# Z32F3841 register map
Vendor: Zilog, Inc; File version: 1.0.1
Z32F3841, ARM 32-bit Cortex-M3 Microcontroller based device.
CPU: CM3 r2p0, little endian, no MPU, no FPU, 3 interrupt priority bits
Registers are 32-bit, read-write, reset 0x0 unless marked. A register's access mark holds for its fields unless they carry their own. Offsets are from the block's base; lines under a group give offsets from that group; [hi:lo] are bit positions; {n}, {i} and the like mark numbered series; 'fields as' and 'values as' point back to an identical list; <NAME> marks a mode.

## Memory map
0x40000000 SCU size 0x100 — SYSTEM CONTROL UNIT
0x40000100 FM size 0x100 — FLASH MEMORY CONTROLLER
0x40000200 WDT size 0x100 — WATCH-DOG TIMER
0x40000400 DC0 size 0x10 — DIRECT MEMORY ACCESS CONTROLLER
0x40000410 DC1 size 0x10
0x40000420 DC2 size 0x10
0x40000430 DC3 size 0x10
0x40000440 DC4 size 0x10
0x40000450 DC5 size 0x10
0x40000460 DC6 size 0x10
0x40000470 DC7 size 0x10
0x40000600 FRT size 0x20 — 32bit Free Run Timer
0x40001000 PCA size 0x100 — PORT CONTROL UNIT
0x40001100 PCB size 0x100
0x40001200 PCC size 0x100
0x40001300 PCD size 0x100
0x40001400 PCE size 0x100
0x40001500 PCF size 0x100
0x40001FF0 PORTEN size 0x10 — Port Access Eable
0x40002000 PA size 0x100 — GENERAL PURPOSE I/O
0x40002100 PB size 0x100
0x40002200 PC size 0x100
0x40002300 PD size 0x100
0x40002400 PE size 0x100
0x40002500 PF size 0x100
0x40003000 T0 size 0x20 — 16-BIT TIMER
{0x40003000+0x20*n} T{n} size 0x20 (n=1..9)
0x40004000 MP0 size 0x1000 — MOTOR PULSE-WIDTH-MODULATOR
0x40005000 MP1 size 0x1000
0x40008000 U0 size 0x100 — UNIVERSAL ASYNCHRONOUS RECEIVER/TRANSMITTER
0x40008100 U1 size 0x100
0x40008200 U2 size 0x100
0x40008300 U3 size 0x100
0x40009000 SP0 size 0x100 — SERIAL PERIPHERAL INTERFACE
0x40009100 SP1 size 0x100
0x4000A000 IC0 size 0x100 — I2C Interface
0x4000A100 IC1 size 0x100
0x4000B000 AD0 size 0x100 — 12-BIT A/D CONVERTER
0x4000B100 AD1 size 0x100

## Interrupts
0 LVDDETECT (SCU)
1 SYSCLKFAIL (SCU)
2 XOSCFAIL (SCU)
3 WDT
4 FRT
{n+5} TIMER{n} (T{n}) (n=0..9)
16 GPIOAE (PCA)
17 GPIOAO (PCA)
18 GPIOBE (PCB)
19 GPIOBO (PCB)
20 GPIOCE (PCC)
21 GPIOCO (PCC)
22 GPIODE (PCD)
23 GPIODO (PCD)
24 MPWM0 (MP0)
25 MPWM0PROT (MP0)
26 MPWM0OVV (MP0)
27 MPWM1 (MP1)
28 MPWM1PROT (MP1)
29 MPWM1OVV (MP1)
32 SPI0 (SP0)
33 SPI1 (SP1)
36 I2C0 (IC0)
37 I2C1 (IC1)
38 UART0 (U0)
39 UART1 (U1)
40 UART2 (U2)
41 UART3 (U3)
43 ADC0 (AD0)
44 ADC1 (AD1)
50 GPIOEE (PCE)
51 GPIOEO (PCE)
52 GPIOFE (PCF)
53 GPIOFO (PCF)

## FM — FLASH MEMORY CONTROLLER
Base 0x40000100
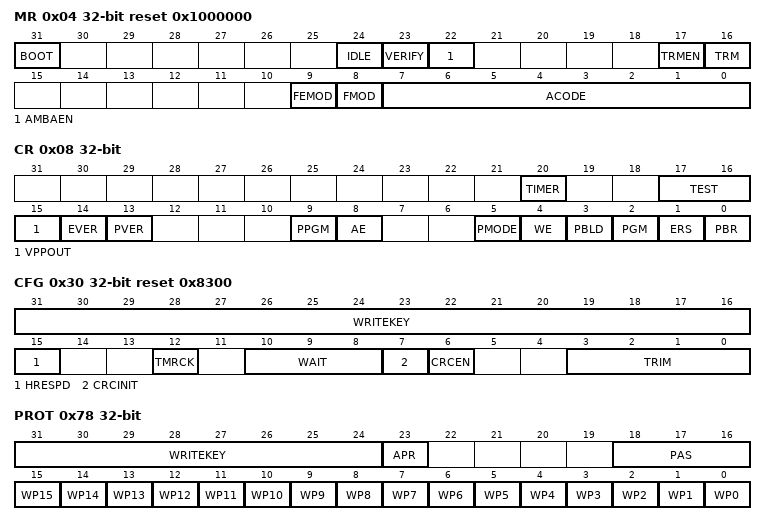
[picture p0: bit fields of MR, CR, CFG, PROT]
0x04 MR reset 0x1000000 — Flash Memory Mode Register
  [31] BOOT ro — Boot Mode enable status
  [24] IDLE ro — Idle mode enable status
  [23] VERIFY — Flash verify Mode enable status
  [22] AMBAEN — AMBA mode enable
  [17] TRMEN ro — Trim Mode entry status
  [16] TRM ro — Trim Mode status
  [9] FEMOD ro — Flash Mode entry status
  [8] FMOD ro — Flash Mode status
  [7:0] ACODE — Flash Mode/Trim Mode
0x08 CR — Flash Memory Control Register
  [20] TIMER — Program/Erase Timer enable
  [17:16] TEST
  [15] VPPOUT — Enable Charge pump VPP output
  [14] EVER — Set Erase Verify mode
  [13] PVER — Set Program Verify mode
  [9] PPGM — PreProgram enable
  [8] AE ro — All Erase
  [5] PMODE — Pmode Enable
  [4] WE — write Enable
  [3] PBLD — page buffer load
  [2] PGM
  [1] ERS — program mode/erase mode Enable
  [0] PBR — page buffer reset
0x0C AR — Flash Memory Address Register
  [16:0] FADDR — 96K 4-byte word address
0x10 DR — Flash Memory Data Register
  [31:0] FDATA — Flash PGM data
0x14 TMR reset 0x9C4 — Flash Memory Timer Register
  [15:0] TMR — Erase/PGM timer
0x18 DRTY — Flash Memory Dirty bit Register
  [31:0] FDRTY — Write any value,cache line fill falg will be cleared
0x1C TICK — Flash Memory Tick Timer register
  [17:0] FTICK — TICK
0x20 CRC — Flash Memory CRC value register
  [15:0] CRC — CRC16 Value
0x30 CFG reset 0x8300 — Flash Memory Config value register
  [31:16] WRITEKEY — Write Key (0x7858)
  [15] HRESPD — Disable AMBA AHB signal (error response)
  [12] TMRCK — PGM/ERASE Timer source
  [10:8] WAIT — Wait for Flash Access
  [7] CRCINIT — Initialize CRC register
  [6] CRCEN — Enable CRC calculation at flash read
  [3:0] TRIM — FLASH TRIM value
0x74 BOOTCR reset 0x1 — Boot ROM Remap Clear Register
  [0] BOOTROM — Used to clear Boot mode at end of boot code
0x78 PROT — Internal flash memory protection Register
  [31:24] WRITEKEY
  [23] APR — Enable/Remove all protection
  [18:16] PAS — Protection Area Selection
  [n] WP{n} (n=0..15) — {0x0+0x1000*n}-{0xFFF+0x1000*n}
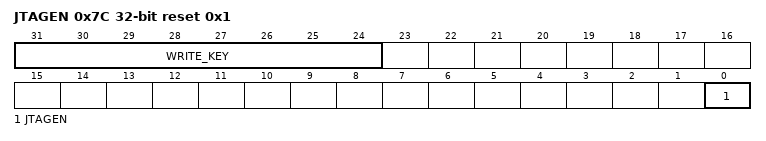
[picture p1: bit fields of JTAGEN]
0x7C JTAGEN reset 0x1 — JTAG Protection Control Register
  [31:24] WRITE_KEY — Write Key (0xC7)
  [0] JTAGEN — JTAG enable

## Licence text in the file
THIS SOFTWARE IS PROVIDED "AS IS". NO WARRANTIES, WHETHER EXPRESS, IMPLIED. OR STATUTORY, INCLUDING, BUT NOT LIMITED TO, IMPLIED WARRANTIES OF. MERCHANTABILITY AND FITNESS FOR A PARTICULAR PURPOSE APPLY TO THIS SOFTWARE. ARM SHALL NOT, IN ANY CIRCUMSTANCES, BE LIABLE FOR SPECIAL, INCIDENTAL, OR. CONSEQUENTIAL DAMAGES, FOR ANY REASON WHATSOEVER.
